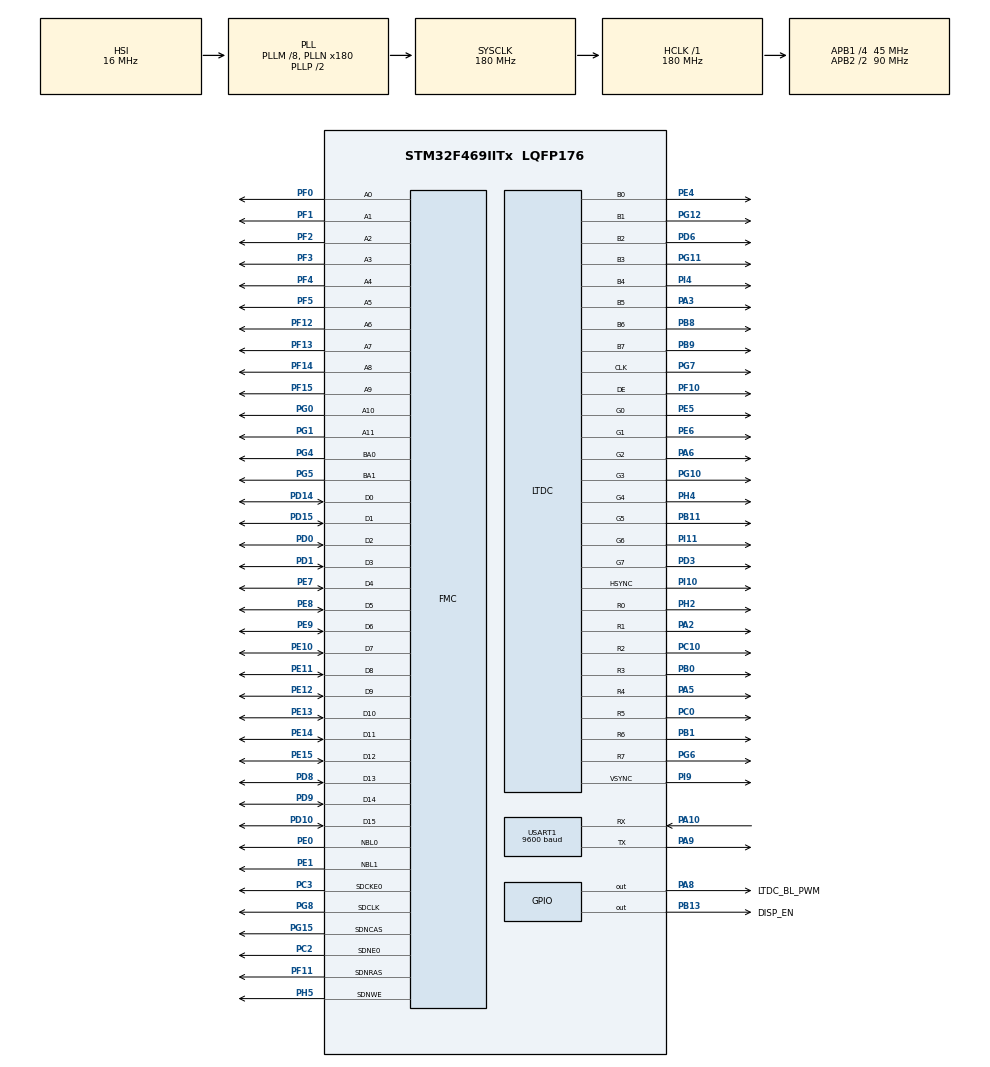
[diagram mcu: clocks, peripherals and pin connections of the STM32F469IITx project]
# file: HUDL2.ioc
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FMC.CASLatency1=FMC_SDRAM_CAS_LATENCY_2
FMC.ExitSelfRefreshDelay1=10
FMC.LoadToActiveDelay1=2
FMC.ReadBurst1=FMC_SDRAM_RBURST_ENABLE
FMC.ReadBurst2=FMC_SDRAM_RBURST_ENABLE
FMC.ReadPipeDelay1=FMC_SDRAM_RPIPE_DELAY_0
FMC.SDClockPeriod1=FMC_SDRAM_CLOCK_PERIOD_2
FMC.SelfRefreshTime1=2
LTDC.ActiveH=480
LTDC.ActiveW=800
LTDC.Alpha0_L0=255
LTDC.Alpha_L0=255
LTDC.BlendingFactor1_L0=LTDC_BLENDING_FACTOR1_PAxCA
LTDC.BlendingFactor2_L0=LTDC_BLENDING_FACTOR2_PAxCA
LTDC.Blue=0x02
LTDC.Blue_L0=255
LTDC.DEPolarity=LTDC_DEPOLARITY_AL
LTDC.FBStartAdress_L0=0xC0000000
LTDC.Green=0x69
LTDC.Green_L0=255
LTDC.HBP=40
LTDC.HFP=40
LTDC.HSync=48
LTDC.ImageHeight_L0=480
LTDC.ImageWidth_L0=800
LTDC.Layers=0
LTDC.PCPolarity=LTDC_PCPOLARITY_IPC
LTDC.PixelFormat_L0=LTDC_PIXEL_FORMAT_RGB888
LTDC.Red=0xF7
LTDC.Red_L0=255
LTDC.VBP=31
LTDC.VFP=13
LTDC.VSync=1
LTDC.WindowX1_L0=800
LTDC.WindowY1_L0=480
Mcu.Family=STM32F4
Mcu.Name=STM32F469IITx
Mcu.Package=LQFP176
NVIC.LTDC_IRQn=true\:0\:0\:false\:false\:true\:true\:true\:true
NVIC.PriorityGroup=NVIC_PRIORITYGROUP_4
PA10.Mode=Asynchronous
PA10.Signal=USART1_RX
PA13.Mode=Serial_Wire
PA13.Signal=SYS_JTMS-SWDIO
PA14.Mode=Serial_Wire
PA14.Signal=SYS_JTCK-SWCLK
PA2.Mode=RGB888
PA2.Signal=LTDC_R1
PA3.Mode=RGB888
PA3.Signal=LTDC_B5
PA5.Mode=RGB888
PA5.Signal=LTDC_R4
PA6.Mode=RGB888
PA6.Signal=LTDC_G2
PA8.GPIO_Label=LTDC_BL_PWM
PA8.PinState=GPIO_PIN_RESET
PA8.Signal=GPIO_Output
PA9.Mode=Asynchronous
PA9.Signal=USART1_TX
PB0.Mode=RGB888
PB0.Signal=LTDC_R3
PB1.Mode=RGB888
PB1.Signal=LTDC_R6
PB11.Mode=RGB888
PB11.Signal=LTDC_G5
PB13.GPIO_Label=DISP_EN
PB13.PinState=GPIO_PIN_RESET
PB13.Signal=GPIO_Output
PB8.Mode=RGB888
PB8.Signal=LTDC_B6
PB9.Mode=RGB888
PB9.Signal=LTDC_B7
PC0.Mode=RGB888
PC0.Signal=LTDC_R5
PC10.Mode=RGB888
PC10.Signal=LTDC_R2
PC2.Mode=SdramChipSelect1_1
PC2.Signal=FMC_SDNE0
PC3.Mode=SdramChipSelect1_1
PC3.Signal=FMC_SDCKE0
PD0.Signal=FMC_D2_DA2
PD1.Signal=FMC_D3_DA3
PD10.Signal=FMC_D15_DA15
PD14.Signal=FMC_D0_DA0
PD15.Signal=FMC_D1_DA1
PD3.Mode=RGB888
PD3.Signal=LTDC_G7
PD6.Mode=RGB888
PD6.Signal=LTDC_B2
PD8.Signal=FMC_D13_DA13
PD9.Signal=FMC_D14_DA14
PE0.Signal=FMC_NBL0
PE1.Signal=FMC_NBL1
PE10.Signal=FMC_D7_DA7
PE11.Signal=FMC_D8_DA8
PE12.Signal=FMC_D9_DA9
PE13.Signal=FMC_D10_DA10
PE14.Signal=FMC_D11_DA11
PE15.Signal=FMC_D12_DA12
PE4.Mode=RGB888
PE4.Signal=LTDC_B0
PE5.Mode=RGB888
PE5.Signal=LTDC_G0
PE6.Mode=RGB888
PE6.Signal=LTDC_G1
PE7.Signal=FMC_D4_DA4
PE8.Signal=FMC_D5_DA5
PE9.Signal=FMC_D6_DA6
PF0.Signal=FMC_A0
PF1.Signal=FMC_A1
PF10.Mode=RGB888
PF10.Signal=LTDC_DE
PF11.Signal=FMC_SDNRAS
PF12.Signal=FMC_A6
PF13.Signal=FMC_A7
PF14.Signal=FMC_A8
PF15.Signal=FMC_A9
PF2.Signal=FMC_A2
PF3.Signal=FMC_A3
PF4.Signal=FMC_A4
PF5.Signal=FMC_A5
PG0.Signal=FMC_A10
PG1.Signal=FMC_A11
PG10.Mode=RGB888
PG10.Signal=LTDC_G3
PG11.Mode=RGB888
PG11.Signal=LTDC_B3
PG12.Mode=RGB888
PG12.Signal=LTDC_B1
PG15.Signal=FMC_SDNCAS
PG4.Signal=FMC_A14_BA0
PG5.Signal=FMC_A15_BA1
PG6.Mode=RGB888
PG6.Signal=LTDC_R7
PG7.Mode=RGB888
PG7.Signal=LTDC_CLK
PG8.Signal=FMC_SDCLK
PH2.Mode=RGB888
PH2.Signal=LTDC_R0
PH4.Mode=RGB888
PH4.Signal=LTDC_G4
PH5.Signal=FMC_SDNWE
PI10.Mode=RGB888
PI10.Signal=LTDC_HSYNC
PI11.Mode=RGB888
PI11.Signal=LTDC_G6
PI4.Mode=RGB888
PI4.Signal=LTDC_B4
PI9.Mode=RGB888
PI9.Signal=LTDC_VSYNC
ProjectManager.HeapSize=0x200
ProjectManager.StackSize=0x400
ProjectManager.TargetToolchain=STM32CubeIDE
RCC.AHBFreq_Value=180000000
RCC.APB1CLKDivider=RCC_HCLK_DIV4
RCC.APB1Freq_Value=45000000
RCC.APB1TimFreq_Value=90000000
RCC.APB2CLKDivider=RCC_HCLK_DIV2
RCC.APB2Freq_Value=90000000
RCC.APB2TimFreq_Value=180000000
RCC.CortexFreq_Value=180000000
RCC.HCLKFreq_Value=180000000
RCC.PLLM=8
RCC.PLLN=180
RCC.PLLSAIN=146
RCC.PLLSAIR=5
RCC.SYSCLKFreq_VALUE=180000000
RCC.SYSCLKSource=RCC_SYSCLKSOURCE_PLLCLK
RCC.USBFreq_Value=90000000
RCC.VCOOutputFreq_Value=360000000
SH.FMC_A0.0=FMC_A0,12b-sda1
SH.FMC_A1.0=FMC_A1,12b-sda1
SH.FMC_A10.0=FMC_A10,12b-sda1
SH.FMC_A11.0=FMC_A11,12b-sda1
SH.FMC_A14_BA0.0=FMC_BA0,FourSdramBanks1
SH.FMC_A15_BA1.0=FMC_BA1,FourSdramBanks1
SH.FMC_A2.0=FMC_A2,12b-sda1
SH.FMC_A3.0=FMC_A3,12b-sda1
SH.FMC_A4.0=FMC_A4,12b-sda1
SH.FMC_A5.0=FMC_A5,12b-sda1
SH.FMC_A6.0=FMC_A6,12b-sda1
SH.FMC_A7.0=FMC_A7,12b-sda1
SH.FMC_A8.0=FMC_A8,12b-sda1
SH.FMC_A9.0=FMC_A9,12b-sda1
SH.FMC_D0_DA0.0=FMC_D0,sd-16b-d1
SH.FMC_D10_DA10.0=FMC_D10,sd-16b-d1
SH.FMC_D11_DA11.0=FMC_D11,sd-16b-d1
SH.FMC_D12_DA12.0=FMC_D12,sd-16b-d1
SH.FMC_D13_DA13.0=FMC_D13,sd-16b-d1
SH.FMC_D14_DA14.0=FMC_D14,sd-16b-d1
SH.FMC_D15_DA15.0=FMC_D15,sd-16b-d1
SH.FMC_D1_DA1.0=FMC_D1,sd-16b-d1
SH.FMC_D2_DA2.0=FMC_D2,sd-16b-d1
SH.FMC_D3_DA3.0=FMC_D3,sd-16b-d1
SH.FMC_D4_DA4.0=FMC_D4,sd-16b-d1
SH.FMC_D5_DA5.0=FMC_D5,sd-16b-d1
SH.FMC_D6_DA6.0=FMC_D6,sd-16b-d1
SH.FMC_D7_DA7.0=FMC_D7,sd-16b-d1
SH.FMC_D8_DA8.0=FMC_D8,sd-16b-d1
SH.FMC_D9_DA9.0=FMC_D9,sd-16b-d1
SH.FMC_NBL0.0=FMC_NBL0,Sd2ByteEnable1
SH.FMC_NBL1.0=FMC_NBL1,Sd2ByteEnable1
SH.FMC_SDCLK.0=FMC_SDCLK,12b-sda1
SH.FMC_SDNCAS.0=FMC_SDNCAS,12b-sda1
SH.FMC_SDNRAS.0=FMC_SDNRAS,12b-sda1
SH.FMC_SDNWE.0=FMC_SDNWE,12b-sda1
STMicroelectronics.X-CUBE-TOUCHGFX.4.26.1.tgfx_buffering_strategy=Double
STMicroelectronics.X-CUBE-TOUCHGFX.4.26.1.tgfx_display_interface=disp_ltdc
STMicroelectronics.X-CUBE-TOUCHGFX.4.26.1.tgfx_location=By Address
STMicroelectronics.X-CUBE-TOUCHGFX.4.26.1.tgfx_pixel_format=RGB888\:24
STMicroelectronics.X-CUBE-TOUCHGFX.4.26.1.tgfx_vsync=vsync_ltdc
STMicroelectronics.X-CUBE-TOUCHGFX.4.26.1_IsPackSelfContextualization=true
USART1.BaudRate=9600
USART1.VirtualMode=VM_ASYNC
board=custom

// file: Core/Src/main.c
/* USER CODE BEGIN Header */
/**
  ******************************************************************************
  * @file           : main.c
  * @brief          : Main program body
  ******************************************************************************
  * @attention
  *
  * Copyright (c) 2025 STMicroelectronics.
  * All rights reserved.
  *
  * This software is licensed under terms that can be found in the LICENSE file
  * in the root directory of this software component.
  * If no LICENSE file comes with this software, it is provided AS-IS.
  *
  ******************************************************************************
  */
/* USER CODE END Header */
#include "main.h"
#include "usart.h"
#include "gpio.h"

/* USER CODE BEGIN Includes */
#include <string.h>
#include <stdio.h>

#include "fmc.h"
#include "ltdc.h"

#include "heap.h"
/* USER CODE END Includes */

void SystemClock_Config(void);

int main(void)
{

  /* MCU Configuration--------------------------------------------------------*/

  /* Reset of all peripherals, Initializes the Flash interface and the Systick. */
  HAL_Init();

  /* Configure the system clock */
  SystemClock_Config();

  /* Initialize all configured peripherals */
  MX_GPIO_Init();
  MX_USART1_UART_Init();
  /* USER CODE BEGIN 2 */
  heap_init();

  MX_LTDC_Init();

//  HAL_GPIO_WritePin(DISP_EN_GPIO_Port, DISP_EN_Pin, GPIO_PIN_SET);
  HAL_Delay(165);
  HAL_GPIO_WritePin(LTDC_BL_PWM_GPIO_Port, LTDC_BL_PWM_Pin, GPIO_PIN_SET);
  draw_frame();
  /* USER CODE END 2 */

  /* Infinite loop */
  while (1)
  {

  }
}

void SystemClock_Config(void)
{
  RCC_OscInitTypeDef RCC_OscInitStruct = {0};
  RCC_ClkInitTypeDef RCC_ClkInitStruct = {0};

  /** Configure the main internal regulator output voltage
  */
  __HAL_RCC_PWR_CLK_ENABLE();
  __HAL_PWR_VOLTAGESCALING_CONFIG(PWR_REGULATOR_VOLTAGE_SCALE1);

  /** Initializes the RCC Oscillators according to the specified parameters
  * in the RCC_OscInitTypeDef structure.
  */
  RCC_OscInitStruct.OscillatorType = RCC_OSCILLATORTYPE_HSI;
  RCC_OscInitStruct.HSIState = RCC_HSI_ON;
  RCC_OscInitStruct.HSICalibrationValue = RCC_HSICALIBRATION_DEFAULT;
  RCC_OscInitStruct.PLL.PLLState = RCC_PLL_ON;
  RCC_OscInitStruct.PLL.PLLSource = RCC_PLLSOURCE_HSI;
  RCC_OscInitStruct.PLL.PLLM = 8;
  RCC_OscInitStruct.PLL.PLLN = 180;
  RCC_OscInitStruct.PLL.PLLP = RCC_PLLP_DIV2;
  RCC_OscInitStruct.PLL.PLLQ = 4;
  RCC_OscInitStruct.PLL.PLLR = 2;
  if (HAL_RCC_OscConfig(&RCC_OscInitStruct) != HAL_OK)
  {
    Error_Handler();
  }

  /** Activate the Over-Drive mode
  */
  if (HAL_PWREx_EnableOverDrive() != HAL_OK)
  {
    Error_Handler();
  }

  /** Initializes the CPU, AHB and APB buses clocks
  */
  RCC_ClkInitStruct.ClockType = RCC_CLOCKTYPE_HCLK|RCC_CLOCKTYPE_SYSCLK
                              |RCC_CLOCKTYPE_PCLK1|RCC_CLOCKTYPE_PCLK2;
  RCC_ClkInitStruct.SYSCLKSource = RCC_SYSCLKSOURCE_PLLCLK;
  RCC_ClkInitStruct.AHBCLKDivider = RCC_SYSCLK_DIV1;
  RCC_ClkInitStruct.APB1CLKDivider = RCC_HCLK_DIV4;
  RCC_ClkInitStruct.APB2CLKDivider = RCC_HCLK_DIV2;

  if (HAL_RCC_ClockConfig(&RCC_ClkInitStruct, FLASH_LATENCY_5) != HAL_OK)
  {
    Error_Handler();
  }
}

void Error_Handler(void)
{
  __disable_irq();
  while (1)
  {
  }
}
